# apps_rcm register map
Vendor: Texas Instruments
Peripheral module from a debugger description file (folder cc32).
Registers are 32-bit, access per field, no defined reset value unless marked. A register's access mark holds for its fields unless they carry their own. Offsets are as the file gives them; lines under a group give offsets from that group; [hi:lo] are bit positions; {n}, {i} and the like mark numbered series; 'fields as' and 'values as' point back to an identical list; <NAME> marks a mode.

## apps_rcm
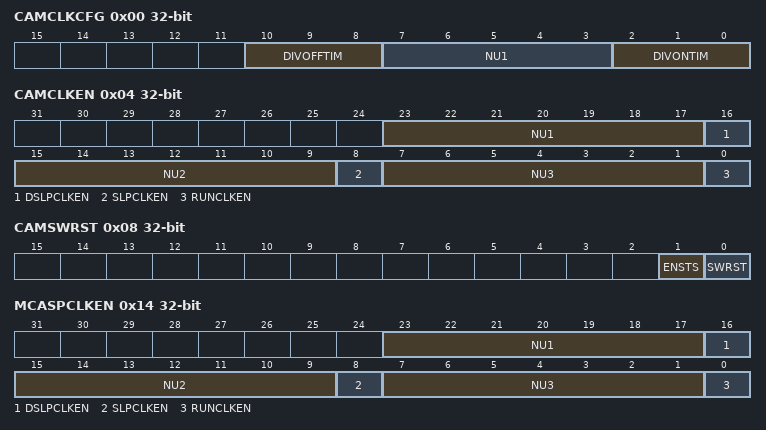
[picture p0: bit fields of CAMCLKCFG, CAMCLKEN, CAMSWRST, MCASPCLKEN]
0x00 CAMCLKCFG
  [10:8] DIVOFFTIM rw — Configuration of OFF-TIME for dividing PLL clk (240 MHz) in generation of Camera func-clk : "000" - 1 "001" - 2 "010" - 3 "011" - 4 "100" - 5 "101" - 6 "110" - 7 "111" - 8
  [7:3] NU1 ro
  [2:0] DIVONTIM rw — Configuration of ON-TIME for dividing PLL clk (240 MHz) in generation of Camera func-clk : "000" - 1 "001" - 2 "010" - 3 "011" - 4 "100" - 5 "101" - 6 "110" - 7 "111" - 8
0x04 CAMCLKEN
  [23:17] NU1 ro
  [16] DSLPCLKEN ro — CAMERA_DSLP_CLK_ENABLE
  [15:9] NU2 ro
  [8] SLPCLKEN rw — CAMERA_SLP_CLK_ENABLE
  [7:1] NU3 ro
  [0] RUNCLKEN rw — CAMERA_RUN_CLK_ENABLE
0x08 CAMSWRST
  [1] ENSTS ro — CAMERA_ENABLED_STATUS
  [0] SWRST rw — CAMERA_SOFT_RESET
0x14 MCASPCLKEN
  [23:17] NU1 ro
  [16] DSLPCLKEN ro — MCASP_DSLP_CLK_ENABLE
  [15:9] NU2 ro
  [8] SLPCLKEN rw — MCASP_SLP_CLK_ENABLE
  [7:1] NU3 ro
  [0] RUNCLKEN rw — MCASP_RUN_CLK_ENABLE
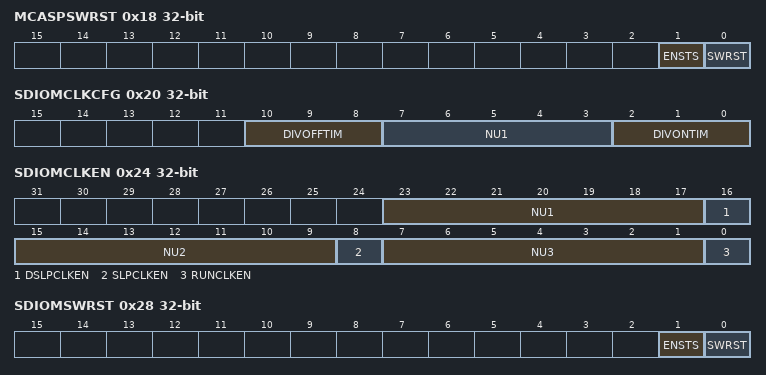
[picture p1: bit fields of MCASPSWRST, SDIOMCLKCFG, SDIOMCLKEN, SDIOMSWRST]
0x18 MCASPSWRST
  [1] ENSTS ro — MCASP_ENABLED_STATUS
  [0] SWRST rw — MCASP_SOFT_RESET
0x20 SDIOMCLKCFG rw
  [10:8] DIVOFFTIM — Configuration of OFF-TIME for dividing PLL clk (240 MHz) in generation of MMCHS func-clk : "000" - 1 "001" - 2 "010" - 3 "011" - 4 "100" - 5 "101" - 6 "110" - 7 "111" - 8
  [7:3] NU1
  [2:0] DIVONTIM — Configuration of ON-TIME for dividing PLL clk (240 MHz) in generation of MMCHS func-clk : "000" - 1 "001" - 2 "010" - 3 "011" - 4 "100" - 5 "101" - 6 "110" - 7 "111" - 8
0x24 SDIOMCLKEN
  [23:17] NU1 ro
  [16] DSLPCLKEN ro — MMCHS_DSLP_CLK_ENABLE
  [15:9] NU2 ro
  [8] SLPCLKEN rw — MMCHS_SLP_CLK_ENABLE
  [7:1] NU3 ro
  [0] RUNCLKEN rw — MMCHS_RUN_CLK_ENABLE
0x28 SDIOMSWRST
  [1] ENSTS ro — MMCHS_ENABLED_STATUS
  [0] SWRST rw — MMCHS_SOFT_RESET
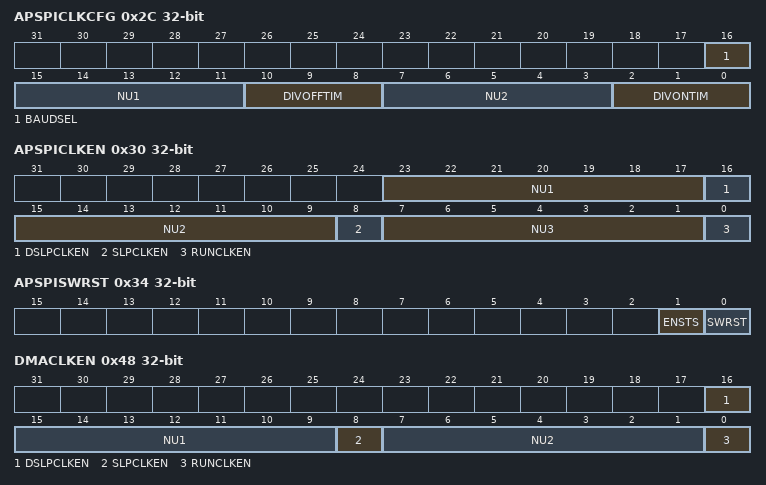
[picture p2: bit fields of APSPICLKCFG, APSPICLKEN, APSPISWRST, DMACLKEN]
0x2C APSPICLKCFG
  [16] BAUDSEL rw — MCSPI_A1_BAUD_CLK_SEL
  [15:11] NU1 ro
  [10:8] DIVOFFTIM rw — Configuration of OFF-TIME for dividing PLL clk (240 MHz) in generation of MCSPI_A1 func-clk : "000" - 1 "001" - 2 "010" - 3 "011" - 4 "100" - 5 "101" - 6 "110" - 7 "111" - 8
  [7:3] NU2 ro
  [2:0] DIVONTIM rw — Configuration of ON-TIME for dividing PLL clk (240 MHz) in generation of MCSPI_A1 func-clk : "000" - 1 "001" - 2 "010" - 3 "011" - 4 "100" - 5 "101" - 6 "110" - 7 "111" - 8
0x30 APSPICLKEN
  [23:17] NU1 ro — Not used
  [16] DSLPCLKEN ro — MCSPI_A1_DSLP_CLK_ENABLE
  [15:9] NU2 ro — Not used
  [8] SLPCLKEN rw — MCSPI_A1_SLP_CLK_ENABLE
  [7:1] NU3 ro — Not used
  [0] RUNCLKEN rw — MCSPI_A1_RUN_CLK_ENABLE
0x34 APSPISWRST
  [1] ENSTS ro — MCSPI_A1_ENABLED_STATUS
  [0] SWRST rw — MCSPI_A1_SOFT_RESET
0x48 DMACLKEN
  [16] DSLPCLKEN rw — UDMA_A_DSLP_CLK_ENABLE
  [15:9] NU1 ro — Not used
  [8] SLPCLKEN rw — UDMA_A_SLP_CLK_ENABLE
  [7:1] NU2 ro — Not used
  [0] RUNCLKEN rw — UDMA_A_RUN_CLK_ENABLE
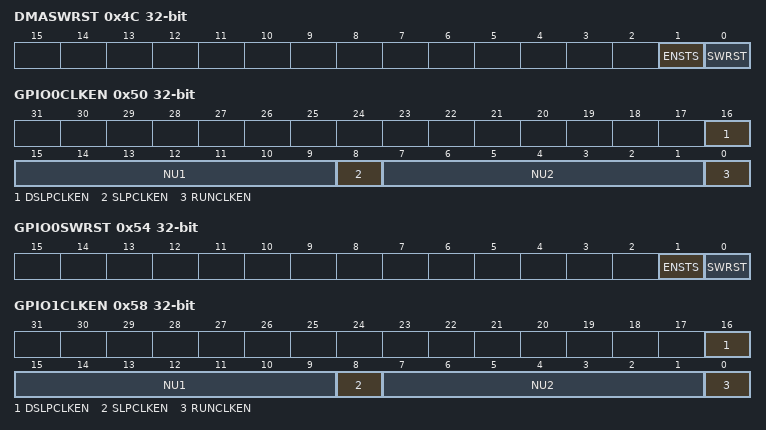
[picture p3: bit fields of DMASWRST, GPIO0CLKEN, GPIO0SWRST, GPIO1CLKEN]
0x4C DMASWRST
  [1] ENSTS ro — UDMA_A_ENABLED_STATUS
  [0] SWRST rw — UDMA_A_SOFT_RESET
0x50 GPIO0CLKEN rw
  [16] DSLPCLKEN — GPIO_A_DSLP_CLK_ENABLE
  [15:9] NU1
  [8] SLPCLKEN — GPIO_A_SLP_CLK_ENABLE
  [7:1] NU2
  [0] RUNCLKEN — GPIO_A_RUN_CLK_ENABLE
0x54 GPIO0SWRST
  [1] ENSTS ro — GPIO_A_ENABLED_STATUS
  [0] SWRST rw — GPIO_A_SOFT_RESET
0x58 GPIO1CLKEN
  [16] DSLPCLKEN rw — GPIO_B_DSLP_CLK_ENABLE
  [15:9] NU1 ro
  [8] SLPCLKEN rw — GPIO_B_SLP_CLK_ENABLE
  [7:1] NU2 ro
  [0] RUNCLKEN rw — GPIO_B_RUN_CLK_ENABLE
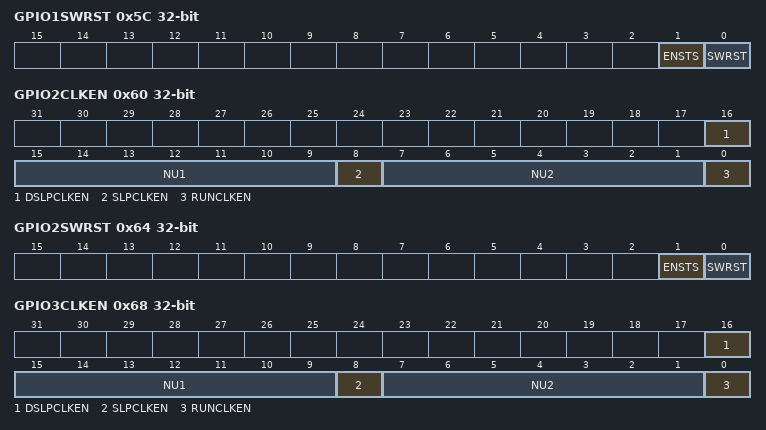
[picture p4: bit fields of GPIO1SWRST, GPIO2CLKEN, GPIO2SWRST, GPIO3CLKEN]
0x5C GPIO1SWRST
  [1] ENSTS ro — GPIO_B_ENABLED_STATUS
  [0] SWRST rw — GPIO_B_SOFT_RESET
0x60 GPIO2CLKEN
  [16] DSLPCLKEN rw — GPIO_C_DSLP_CLK_ENABLE
  [15:9] NU1 ro
  [8] SLPCLKEN rw — GPIO_C_SLP_CLK_ENABLE
  [7:1] NU2 ro
  [0] RUNCLKEN rw — GPIO_C_RUN_CLK_ENABLE
0x64 GPIO2SWRST
  [1] ENSTS ro — GPIO_C_ENABLED_STATUS
  [0] SWRST rw — GPIO_C_SOFT_RESET
0x68 GPIO3CLKEN
  [16] DSLPCLKEN rw — GPIO_D_DSLP_CLK_ENABLE
  [15:9] NU1 ro
  [8] SLPCLKEN rw — GPIO_D_SLP_CLK_ENABLE
  [7:1] NU2 ro
  [0] RUNCLKEN rw — GPIO_D_RUN_CLK_ENABLE
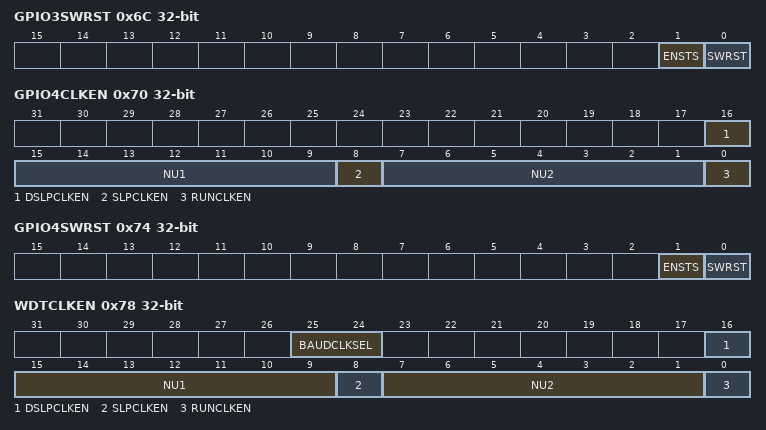
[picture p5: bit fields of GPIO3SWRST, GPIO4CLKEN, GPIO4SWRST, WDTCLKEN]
0x6C GPIO3SWRST
  [1] ENSTS ro — GPIO_D_ENABLED_STATUS
  [0] SWRST rw — GPIO_D_SOFT_RESET
0x70 GPIO4CLKEN
  [16] DSLPCLKEN rw — GPIO_E_DSLP_CLK_ENABLE
  [15:9] NU1 ro
  [8] SLPCLKEN rw — GPIO_E_SLP_CLK_ENABLE
  [7:1] NU2 ro
  [0] RUNCLKEN rw — GPIO_E_RUN_CLK_ENABLE
0x74 GPIO4SWRST
  [1] ENSTS ro — GPIO_E_ENABLED_STATUS
  [0] SWRST rw — GPIO_E_SOFT_RESET
0x78 WDTCLKEN
  [25:24] BAUDCLKSEL rw — "00" - Sysclk ; "01" - REF_CLK (38.4 MHz) ; "10/11" - Slow_clk
  [16] DSLPCLKEN rw — WDOG_A_DSLP_CLK_ENABLE
  [15:9] NU1 ro
  [8] SLPCLKEN rw — WDOG_A_SLP_CLK_ENABLE
  [7:1] NU2 ro
  [0] RUNCLKEN rw — WDOG_A_RUN_CLK_ENABLE
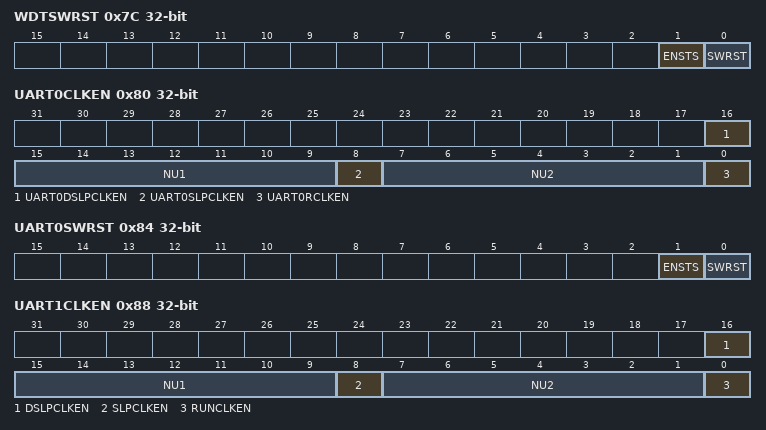
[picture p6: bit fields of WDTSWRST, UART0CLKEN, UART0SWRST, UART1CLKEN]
0x7C WDTSWRST
  [1] ENSTS ro — WDOG_A_ENABLED_STATUS
  [0] SWRST rw — WDOG_A_SOFT_RESET
0x80 UART0CLKEN
  [16] UART0DSLPCLKEN rw — UART_A0_DSLP_CLK_ENABLE
  [15:9] NU1 ro
  [8] UART0SLPCLKEN rw — UART_A0_SLP_CLK_ENABLE
  [7:1] NU2 ro
  [0] UART0RCLKEN rw — UART_A0_RUN_CLK_ENABLE
0x84 UART0SWRST
  [1] ENSTS ro — UART_A0_ENABLED_STATUS
  [0] SWRST rw — UART_A0_SOFT_RESET
0x88 UART1CLKEN
  [16] DSLPCLKEN rw — UART_A1_DSLP_CLK_ENABLE
  [15:9] NU1 ro
  [8] SLPCLKEN rw — UART_A1_SLP_CLK_ENABLE
  [7:1] NU2 ro
  [0] RUNCLKEN rw — UART_A1_RUN_CLK_ENABLE
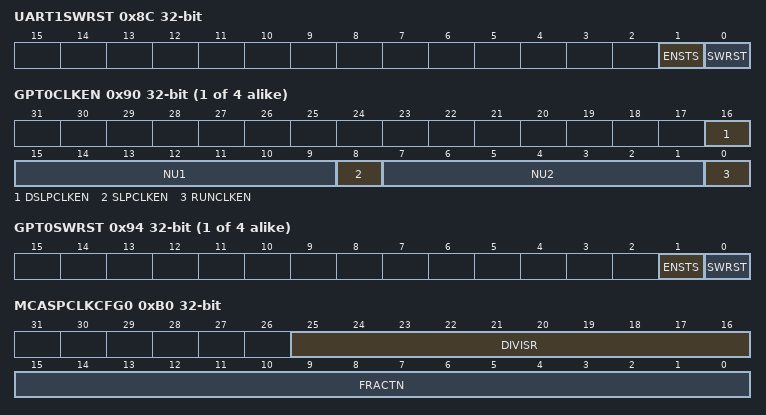
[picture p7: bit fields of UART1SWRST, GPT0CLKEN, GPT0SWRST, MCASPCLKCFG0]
0x8C UART1SWRST
  [1] ENSTS ro — UART_A1_ENABLED_STATUS
  [0] SWRST rw — UART_A1_SOFT_RESET
{0x90+8i} GPT{i}CLKEN (i=0..3)
  [16] DSLPCLKEN rw — GPT_A{i}_DSLP_CLK_ENABLE
  [15:9] NU1 ro
  [8] SLPCLKEN rw — GPT_A{i}_SLP_CLK_ENABLE
  [7:1] NU2 ro
  [0] RUNCLKEN rw — GPT_A{i}_RUN_CLK_ENABLE
{0x94+8i} GPT{i}SWRST (i=0..3)
  [1] ENSTS ro — GPT_A{i}_ENABLED_STATUS
  [0] SWRST rw — GPT_A{i}_SOFT_RESET
0xB0 MCASPCLKCFG0 rw
  [25:16] DIVISR — MCASP_FRAC_DIV_DIVISOR
  [15:0] FRACTN — MCASP_FRAC_DIV_FRACTION
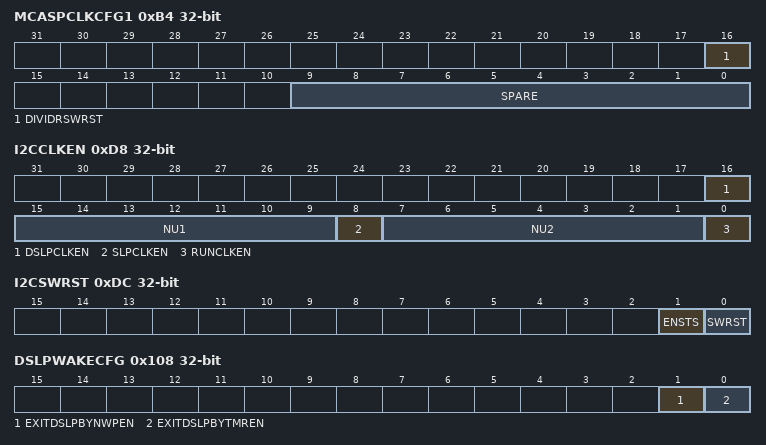
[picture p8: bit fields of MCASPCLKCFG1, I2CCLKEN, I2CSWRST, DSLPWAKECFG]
0xB4 MCASPCLKCFG1 rw
  [16] DIVIDRSWRST — MCASP_FRAC_DIV_SOFT_RESET
  [9:0] SPARE — MCASP_FRAC_DIV_PERIOD
0xD8 I2CCLKEN
  [16] DSLPCLKEN rw — I2C_DSLP_CLK_ENABLE
  [15:9] NU1 ro
  [8] SLPCLKEN rw — I2C_SLP_CLK_ENABLE
  [7:1] NU2 ro
  [0] RUNCLKEN rw — I2C_RUN_CLK_ENABLE
0xDC I2CSWRST
  [1] ENSTS ro — I2C_ENABLED_STATUS
  [0] SWRST rw — I2C_SOFT_RESET
0xE4 LPDSREQ rw
  [0] LPDSREQ — APPS_LPDS_REQ
0xEC TURBOREQ rw
  [0] TURBOREQ — APPS_TURBO_REQ
0x108 DSLPWAKECFG rw
  [1] EXITDSLPBYNWPEN — DSLP_WAKE_FROM_NWP_ENABLE
  [0] EXITDSLPBYTMREN — DLSP_WAKE_FROM_TIMER_ENABLE
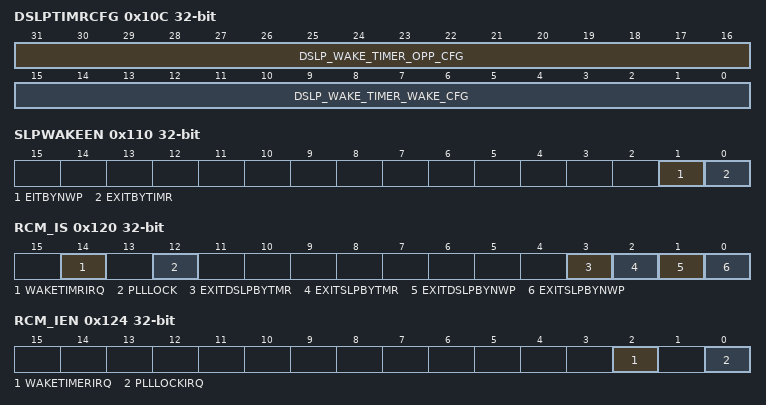
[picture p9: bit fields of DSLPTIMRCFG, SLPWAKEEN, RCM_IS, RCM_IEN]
0x10C DSLPTIMRCFG rw
  [31:16] DSLP_WAKE_TIMER_OPP_CFG — Configuration (in slow_clks) which says when to request for OPP during deep-sleep exit
  [15:0] DSLP_WAKE_TIMER_WAKE_CFG — Configuration (in slow_clks) which says when to request for WAKE during deep-sleep exit
0x110 SLPWAKEEN rw
  [1] EITBYNWP — SLP_WAKE_FROM_NWP_ENABLE
  [0] EXITBYTIMR — SLP_WAKE_TIMER_ENABLE
0x114 SLPTMRCFG rw
  [31:0] TMRCFG — SLP_WAKE_TIMER_CFG
0x118 WAKENWP rw
  [0] WAKENWP — APPS_TO_NWP_WAKEUP_REQUEST
0x120 RCM_IS ro
  [14] WAKETIMRIRQ, [12] PLLLOCK, [3] EXITDSLPBYTMR, [2] EXITSLPBYTMR, [1] EXITDSLPBYNWP, [0] EXITSLPBYNWP
0x124 RCM_IEN rw
  [2] WAKETIMERIRQ, [0] PLLLOCKIRQ
